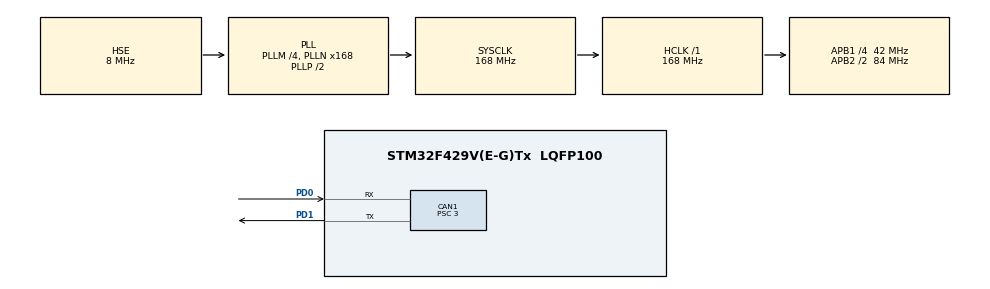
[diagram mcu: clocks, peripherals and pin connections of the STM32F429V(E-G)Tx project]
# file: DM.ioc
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CAN1.BS1=CAN_BS1_12TQ
CAN1.CalculateBaudRate=1000000
CAN1.CalculateTimeBit=1000
CAN1.CalculateTimeQuantum=71.42857142857143
CAN1.Prescaler=3
Mcu.Family=STM32F4
Mcu.Name=STM32F429V(E-G)Tx
Mcu.Package=LQFP100
NVIC.CAN1_RX0_IRQn=true\:0\:0\:false\:false\:true\:true\:true\:true
NVIC.PriorityGroup=NVIC_PRIORITYGROUP_4
PA13.Mode=Serial_Wire
PA13.Signal=SYS_JTMS-SWDIO
PA14.Mode=Serial_Wire
PA14.Signal=SYS_JTCK-SWCLK
PD0.Mode=CAN_Activate
PD0.Signal=CAN1_RX
PD1.Mode=CAN_Activate
PD1.Signal=CAN1_TX
PH0/OSC_IN.Mode=HSE-External-Oscillator
PH0/OSC_IN.Signal=RCC_OSC_IN
PH1/OSC_OUT.Mode=HSE-External-Oscillator
PH1/OSC_OUT.Signal=RCC_OSC_OUT
ProjectManager.HeapSize=0x200
ProjectManager.StackSize=0x400
ProjectManager.TargetToolchain=MDK-ARM V5.32
RCC.48MHZClocksFreq_Value=84000000
RCC.AHBFreq_Value=168000000
RCC.APB1CLKDivider=RCC_HCLK_DIV4
RCC.APB1Freq_Value=42000000
RCC.APB1TimFreq_Value=84000000
RCC.APB2CLKDivider=RCC_HCLK_DIV2
RCC.APB2Freq_Value=84000000
RCC.APB2TimFreq_Value=168000000
RCC.CortexFreq_Value=168000000
RCC.HCLKFreq_Value=168000000
RCC.HSE_VALUE=8000000
RCC.HSI_VALUE=16000000
RCC.LSE_VALUE=32768
RCC.PLLM=4
RCC.PLLN=168
RCC.PLLSourceVirtual=RCC_PLLSOURCE_HSE
RCC.SYSCLKFreq_VALUE=168000000
RCC.SYSCLKSource=RCC_SYSCLKSOURCE_PLLCLK
RCC.VCOOutputFreq_Value=336000000
board=custom

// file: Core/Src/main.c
/* USER CODE BEGIN Header */
/**
 ******************************************************************************
 * @file           : main.c
 * @brief          : Main program body
 ******************************************************************************
 * @attention
 *
 * Copyright (c) 2026 STMicroelectronics.
 * All rights reserved.
 *
 * This software is licensed under terms that can be found in the LICENSE file
 * in the root directory of this software component.
 * If no LICENSE file comes with this software, it is provided AS-IS.
 *
 ******************************************************************************
 */
/* USER CODE END Header */
#include "main.h"
#include "can.h"
#include "gpio.h"

/* USER CODE BEGIN Includes */
#include "bsp_can.h"
#include "RS02.h"
#include "Dji3508.h"

//#include "RobStride.h"
/* USER CODE END Includes */

/* USER CODE BEGIN PV */
//RobStride_Motor motor1;
RobStride_Motor motor1;
Motor3LoopCtrl_t motor1_3loop;
extern CAN_HandleTypeDef hcan1; // 外部声明CAN句柄
uint8_t rxData[8] = {0};
/* USER CODE END PV */

void SystemClock_Config(void);
/* USER CODE BEGIN PFP */
// RS02相关函数声明
/* USER CODE END PFP */

int main(void)
{

  /* MCU Configuration--------------------------------------------------------*/

  /* Reset of all peripherals, Initializes the Flash interface and the Systick. */
  HAL_Init();

  /* Configure the system clock */
  SystemClock_Config();

  /* Initialize all configured peripherals */
  MX_GPIO_Init();
  MX_CAN1_Init();
  /* USER CODE BEGIN 2 */
  // RS02和3508电机的can总线同时初始化
	RS02_UserInit();
  // 3508的三环控制器初始化
  Motor3Loop_Init(&motor1_3loop);
  // RS02电机初始化
  /* USER CODE END 2 */

  /* Infinite loop */
  /* USER CODE BEGIN WHILE */
  while (1)
  {
	RS02_Task();
    motor1_3loop.target_speed = 500;
	int16_t cur_cmd = Motor3Loop_Update(&motor1_3loop, &moto_chassis[1], 1); // 1表示恒速模式
    send_chassis_cur1_4(0, cur_cmd, 0);
    HAL_Delay(10);
    /* USER CODE END WHILE */

  }
}

void SystemClock_Config(void)
{
  RCC_OscInitTypeDef RCC_OscInitStruct = {0};
  RCC_ClkInitTypeDef RCC_ClkInitStruct = {0};

  /** Configure the main internal regulator output voltage
   */
  __HAL_RCC_PWR_CLK_ENABLE();
  __HAL_PWR_VOLTAGESCALING_CONFIG(PWR_REGULATOR_VOLTAGE_SCALE1);

  /** Initializes the RCC Oscillators according to the specified parameters
   * in the RCC_OscInitTypeDef structure.
   */
  RCC_OscInitStruct.OscillatorType = RCC_OSCILLATORTYPE_HSE;
  RCC_OscInitStruct.HSEState = RCC_HSE_ON;
  RCC_OscInitStruct.PLL.PLLState = RCC_PLL_ON;
  RCC_OscInitStruct.PLL.PLLSource = RCC_PLLSOURCE_HSE;
  RCC_OscInitStruct.PLL.PLLM = 4;
  RCC_OscInitStruct.PLL.PLLN = 168;
  RCC_OscInitStruct.PLL.PLLP = RCC_PLLP_DIV2;
  RCC_OscInitStruct.PLL.PLLQ = 4;
  if (HAL_RCC_OscConfig(&RCC_OscInitStruct) != HAL_OK)
  {
    Error_Handler();
  }

  /** Initializes the CPU, AHB and APB buses clocks
   */
  RCC_ClkInitStruct.ClockType = RCC_CLOCKTYPE_HCLK | RCC_CLOCKTYPE_SYSCLK | RCC_CLOCKTYPE_PCLK1 | RCC_CLOCKTYPE_PCLK2;
  RCC_ClkInitStruct.SYSCLKSource = RCC_SYSCLKSOURCE_PLLCLK;
  RCC_ClkInitStruct.AHBCLKDivider = RCC_SYSCLK_DIV1;
  RCC_ClkInitStruct.APB1CLKDivider = RCC_HCLK_DIV4;
  RCC_ClkInitStruct.APB2CLKDivider = RCC_HCLK_DIV2;

  if (HAL_RCC_ClockConfig(&RCC_ClkInitStruct, FLASH_LATENCY_5) != HAL_OK)
  {
    Error_Handler();
  }
}

///* USER CODE BEGIN 4 */
///**
// * @brief  CAN 接收 FIFO0 消息 pending 回调
// * @param  hcan: 指向 CAN 外设句柄
// * @note   同时解析 RS02 电机和 DJI 3508 电机的反馈
// */
void HAL_CAN_RxFifo0MsgPendingCallback(CAN_HandleTypeDef *hcan)
{
  CAN_RxHeaderTypeDef rxHeader; // 接收帧头
  // 仅处理 CAN1 总线消息
  if (hcan->Instance != CAN1)
  {
    return;
  }

  // 从 FIFO0 获取一条 CAN 消息
  if (HAL_CAN_GetRxMessage(hcan, CAN_RX_FIFO0, &rxHeader, rxData) != HAL_OK)
  {
    return;
  }

  if (rxHeader.IDE == CAN_ID_EXT)
  {
    // ------------------------------
    // RS02 / RobStride 电机反馈：扩展帧
    // 通过 ID_ExtId 解析电机数据
    // ------------------------------
	RobStride_Motor_Analysis(&motor1, rxData, rxHeader.ExtId);
//    RS02_CAN_Analysis_C(rxData, rxHeader.ExtId);
  }
  else if (rxHeader.IDE == CAN_ID_STD)
  {
    // ------------------------------
    // DJI 3508 电机反馈：标准帧 0x201~0x204
    // 解析每个电机的角度、速度和电流
    // ------------------------------
    switch (rxHeader.StdId)
    {
    case CAN_2006_M1_ID:
    case CAN_2006_M2_ID:
    case CAN_2006_M3_ID:
    case CAN_2006_M4_ID:
    {
      // 根据 StdId 计算电机索引
      uint8_t i = rxHeader.StdId - CAN_2006_M1_ID;

      // 更新电机角度和速度数据
      get_motor_measure(&moto_chassis[i], rxData);
      // 计算累计总角度
      get_total_angle(&moto_chassis[i]);
      break;
    }
      // default:
      //   RobStride_Motor_Analysis(&motor1, rxData, rxHeader.StdId);
      //   break;
    }
  }
}
/* USER CODE END 4 */

void Error_Handler(void)
{
  __disable_irq();
  while (1)
  {
  }
}
